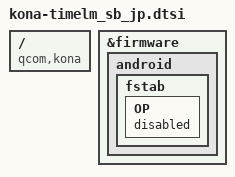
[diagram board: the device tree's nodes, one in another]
// SPDX-License-Identifier: GPL-2.0-only
/*
 * LG V60 ThinQ 5G (timelm) sb_jp, 4.19 CONFIG_MACH_KONA_TIMELM_SB_JP.
 * Shared by the kona-timelm_sb_jp_rev-*.dts leaves, as LG
 * kona-timelm_sb_jp/kona-timelm_sb_jp.dtsi is shared by its rev overlays.
 */

/* Sony CXD2252 NFC (stock cxd22xx-i2c@28 on qupv3_se1_i2c) */
#include "kona-timelm-nfc.dtsi"

/ {
	compatible = "qcom,kona", "lg,timelm";
};

/* JP partition tables have no OP; a crossflashed phone has one, leave it unused */
&firmware {
	android {
		fstab {
			OP {
				status = "disabled";
			};
		};
	};
};
